AUTOSAR XML (schema 4-0-3)
package /AUTOSAR_ComM/SwComponentTypes
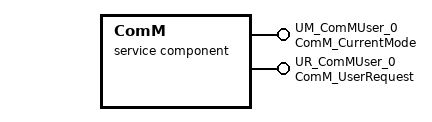
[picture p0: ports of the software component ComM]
  service sw component type ComM
    provide port UM_ComMUser_0: mode-switch-sender-com-spec{mode-group=currentMode, queue-length=3}, provided-interface=ComM_CurrentMode
    provide port UR_ComMUser_0: provided-interface=ComM_UserRequest
      provided-com-specs:
        operation=RequestComMode, queue-length=1
        operation=GetCurrentComMode, queue-length=1
        operation=GetCurrentPNCComMode, queue-length=1
        operation=GetMaxComMode, queue-length=1
        operation=GetRequestedComMode, queue-length=1
    behavior SwcInternalBehavior_0: data-type-mapping=DataTypeMappingSet_0, handle-termination-and-restart=NO-SUPPORT
      5 x operation invoked event:
        EV_RequestComMode_ComMUser_0: start-on-event=RE_RequestComMode, operation=UR_ComMUser_0.RequestComMode
        EV_GetCurrentComMode_ComMUser_0: start-on-event=RE_GetCurrentComMode, operation=UR_ComMUser_0.GetCurrentComMode
        EV_GetCurrentPNCComMode_ComMUser_0: start-on-event=RE_GetCurrentPNCComMode, operation=UR_ComMUser_0.GetCurrentPNCComMode
        EV_GetMaxComMode_ComMUser_0: start-on-event=RE_GetMaxComMode, operation=UR_ComMUser_0.GetMaxComMode
        EV_GetRequestedComMode_ComMUser_0: start-on-event=RE_GetRequestedComMode, operation=UR_ComMUser_0.GetRequestedComMode
      port-api-options:
        enable-take-address=true, indirect-api=false, port=UM_ComMUser_0
        {enable-take-address=false, indirect-api=false, port-defined-argument-value{value=0, value-type=ComM_UserHandleType}, port=UR_ComMUser_0}
      6 x runnable:
        RE_RequestComMode: arguments=[symbol=pdav0, symbol=ComMode], can-be-invoked-concurrently=true, symbol=ComM_Rte_RequestComMode
        RE_GetCurrentComMode: arguments=[symbol=pdav0, symbol=ComMode], can-be-invoked-concurrently=true, symbol=ComM_Rte_GetCurrentComMode
        RE_GetCurrentPNCComMode: arguments=[symbol=pdav0, symbol=ComMode], can-be-invoked-concurrently=true, symbol=ComM_Rte_GetCurrentPNCComMode
        RE_GetMaxComMode: arguments=[symbol=pdav0, symbol=ComMode], can-be-invoked-concurrently=true, symbol=ComM_Rte_GetMaxComMode
        RE_GetRequestedComMode: arguments=[symbol=pdav0, symbol=ComMode], can-be-invoked-concurrently=true, symbol=ComM_Rte_GetRequestedComMode
        RE_Main_0: symbol=ComM_MainFunction_0
          mode switch point MSP_ComMUser_0: mode-group=UM_ComMUser_0.currentMode
package /EB_ComM/SwcImplementations
  swc implementation SwcImplementation_0: programming-language=C, sw-version=5.21.1, vendor-id=1, behavior=SwcInternalBehavior_0
    code-descriptors:
      code ComMCode: artifact-descriptors=autosar-engineering-object={short-label=EngObject, category=SWSRC}
    resource consumption Resources
      memory section CODE: sw-addrmethod=CODE
